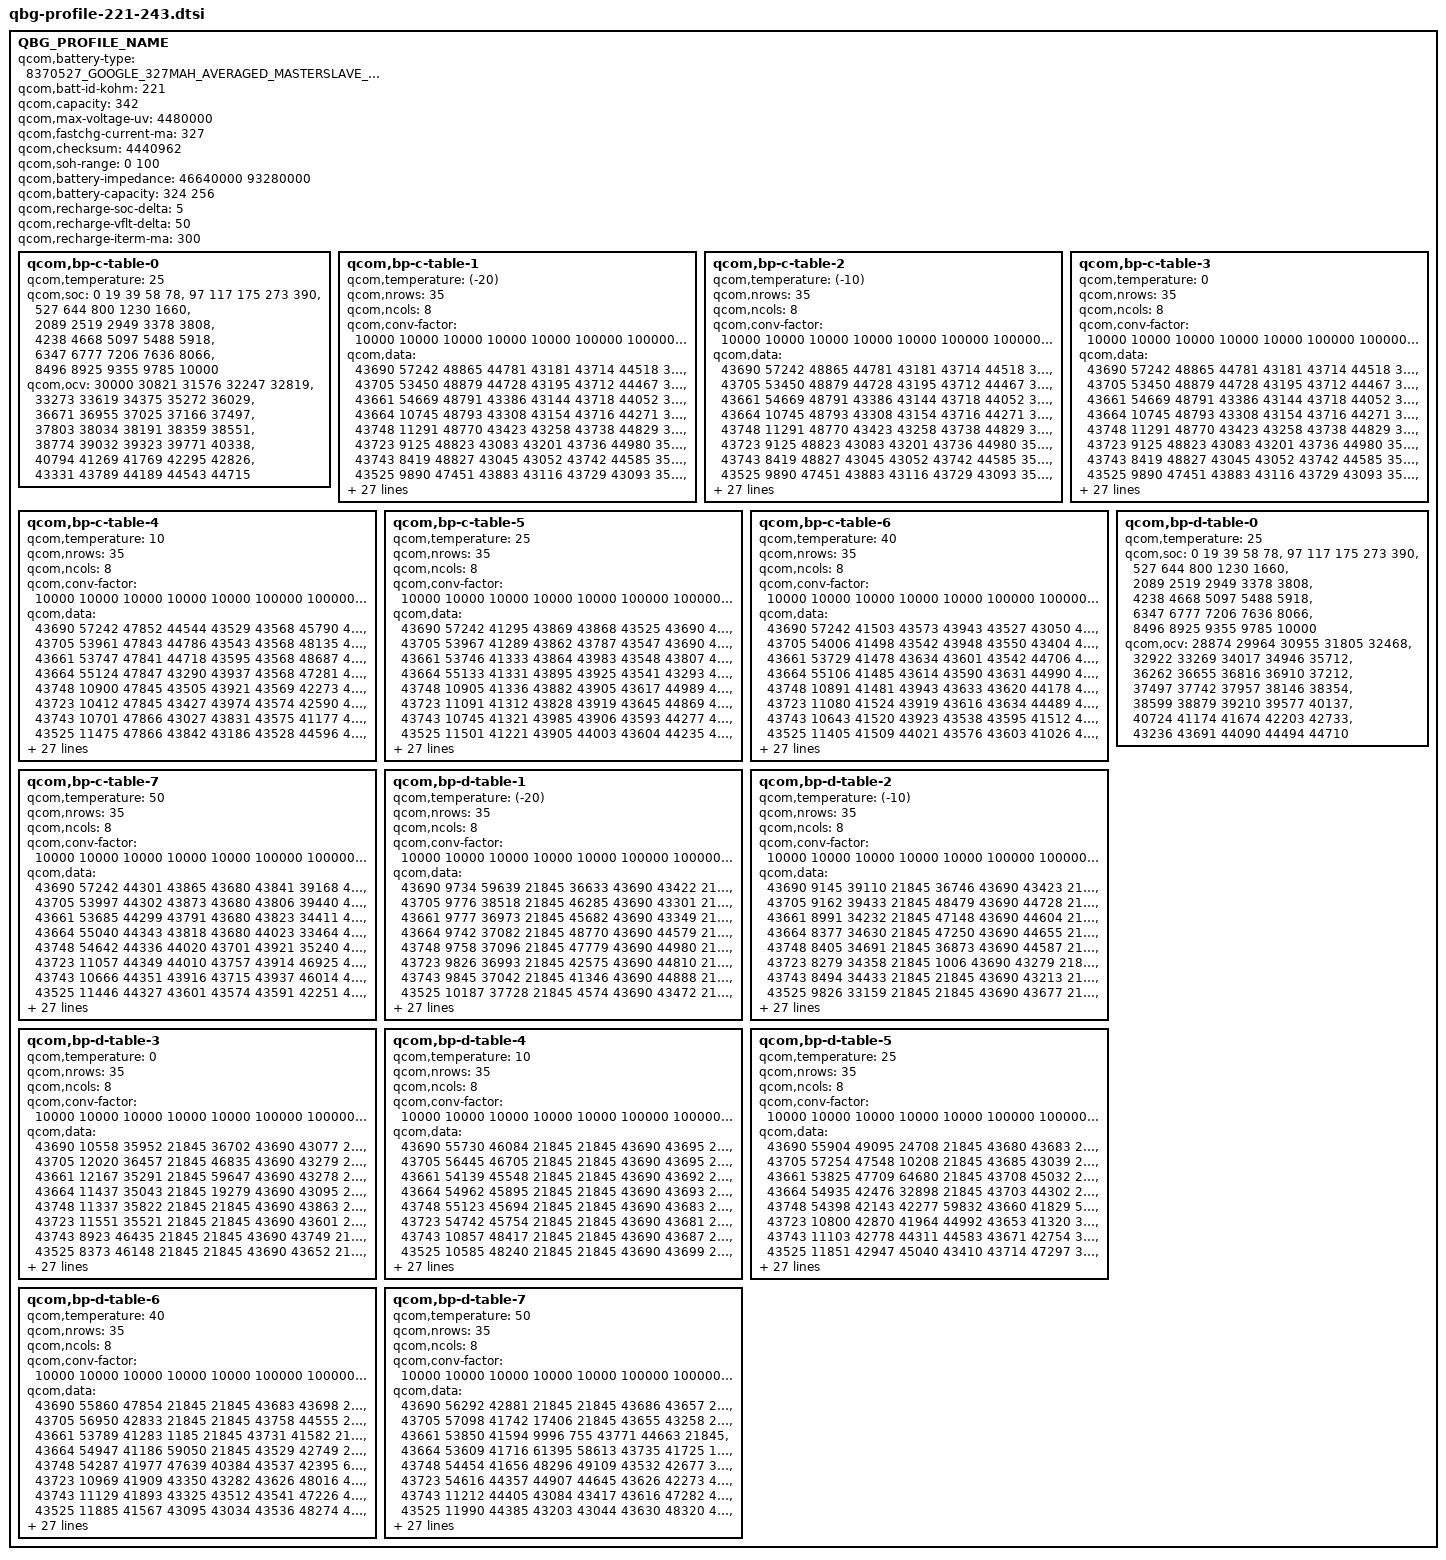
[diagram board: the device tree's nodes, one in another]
/*QBG Profiling Rev. 2.8*/

QBG_PROFILE_NAME {
	qcom,battery-type = "8370527_GOOGLE_327MAH_AVERAGED_MASTERSLAVE_MAR9TH2026";
	qcom,batt-id-kohm = <221>;
	qcom,capacity = <342>;
	qcom,max-voltage-uv = <4480000>;
	qcom,fastchg-current-ma = <327>;
	qcom,checksum = <4440962>; /*@5, 0.005V, 4% */
	qcom,soh-range = <0 100>;
	qcom,battery-impedance = <46640000 93280000>; /*Nominal_Impedance in 10nohm @ SOC 50% 25C* 0:fresh cell, 1: aged cell*/
	qcom,battery-capacity = <324 256>; /*Nominal_Capacity in mAh. 0: fresh cell, 1:aged cell*/ 
	qcom,recharge-soc-delta =<5>; /*SOC delta (in percent) dropped from EOC SOC to enable recharge*/ 
	qcom,recharge-vflt-delta =<50>; /*vfloat delta (in mV) dropped from regular vfloat in recharge*/ 
	qcom,recharge-iterm-ma = <300>; /*termination current (in mA) in recharge*/ 

	qcom,bp-c-table-0 {
		qcom,temperature = <25>;
		qcom,soc = <    0    19    39    58    78>,
			<   97   117   175   273   390>,
			<  527   644   800  1230  1660>,
			< 2089  2519  2949  3378  3808>,
			< 4238  4668  5097  5488  5918>,
			< 6347  6777  7206  7636  8066>,
			< 8496  8925  9355  9785 10000>;
		qcom,ocv = <30000 30821 31576 32247 32819>,
			<33273 33619 34375 35272 36029>,
			<36671 36955 37025 37166 37497>,
			<37803 38034 38191 38359 38551>,
			<38774 39032 39323 39771 40338>,
			<40794 41269 41769 42295 42826>,
			<43331 43789 44189 44543 44715>;
	};
	qcom,bp-c-table-1 {
		qcom,temperature = <(-20)>;
		qcom,nrows = <35>;
		qcom,ncols = <8>;
		qcom,conv-factor = <10000 10000 10000 10000 10000 100000 100000 10000>;
		qcom,data = <43690 57242 48865 44781 43181 43714 44518 34949>,
			<43705 53450 48879 44728 43195 43712 44467 35673>,
			<43661 54669 48791 43386 43144 43718 44052 35615>,
			<43664 10745 48793 43308 43154 43716 44271 35804>,
			<43748 11291 48770 43423 43258 43738 44829 35740>,
			<43723  9125 48823 43083 43201 43736 44980 35420>,
			<43743  8419 48827 43045 43052 43742 44585 35344>,
			<43525  9890 47451 43883 43116 43729 43093 35511>,
			<43963  9355 47456 44030 43131 43565 43225 46381>,
			<43820  9561 47435 43532 43474 43733 43834 46339>,
			<43173 14911 47432 43571 43473 43564 43809 46381>,
			<43054 14946 47475 43541 43506 43558 43807 46550>,
			<43402 15278 47474 43942 43437 43583 43189 46548>,
			<44644 14478 48650 43991 44551 43554 43804 35059>,
			<44246 14827 49111 41476 43820 43528 45996 36323>,
			<41603 16105 48957 41159 43843 43581 45625 33694>,
			<41853 15937 49052 41433 43200 43577 49052 33016>,
			<41263 16333 49107 41329 43104 43556 47500 33254>,
			<42904 16197 48934 42725 43451 43552 47156 34552>,
			<42058 15421 48914 42609 43501 43564 47219 34754>,
			<47652 15832 48984 42954 43511 43560 47503 33998>,
			<47254 12862 48306 42862 43466 43735 47241 34194>,
			<47427 12462 48165 42148 43476 43730 42561 39576>,
			<49114 12738 48216 42211 44713 43736 41580 39694>,
			<48564 14249 48533 42017 44610 43718 44201 39195>,
			<45665 13342 48402 42072 44865 43724 44544 40092>,
			<45267  2768 45809 42445 44454 43720 43342 37812>,
			<46732  2300 45668 42290 41510 43765 43409 38626>,
			<46974  3820 46029 42288 41018 43764 43012 38221>,
			<46376  3306 45914 47778 42526 43722 43221 61178>,
			<35738   670 45278 47705 42281 43723 43211 57531>,
			<34935   160 45123 48016 48769 43720 43161 64323>,
			<36385   274 45557 47628 46832 43722 43903 63135>,
			<35987  2018 45390 42845 34825 43760 43968 51678>,
			<36282  1198 45400 47649 48443 43715 43803 62626>;
	};
	qcom,bp-c-table-2 {
		qcom,temperature = <(-10)>;
		qcom,nrows = <35>;
		qcom,ncols = <8>;
		qcom,conv-factor = <10000 10000 10000 10000 10000 100000 100000 10000>;
		qcom,data = <43690 57242 48865 44781 43181 43714 44518 34949>,
			<43705 53450 48879 44728 43195 43712 44467 35673>,
			<43661 54669 48791 43386 43144 43718 44052 35615>,
			<43664 10745 48793 43308 43154 43716 44271 35804>,
			<43748 11291 48770 43423 43258 43738 44829 35740>,
			<43723  9125 48823 43083 43201 43736 44980 35420>,
			<43743  8419 48827 43045 43052 43742 44585 35344>,
			<43525  9890 47451 43883 43116 43729 43093 35511>,
			<43963  9355 47456 44030 43131 43565 43225 46381>,
			<43820  9561 47435 43532 43474 43733 43834 46339>,
			<43173 14911 47432 43571 43473 43564 43809 46381>,
			<43054 14946 47475 43541 43506 43558 43807 46550>,
			<43402 15278 47474 43942 43437 43583 43189 46548>,
			<44644 14478 48650 43991 44551 43554 43804 35059>,
			<44246 14827 49111 41476 43820 43528 45996 36323>,
			<41603 16105 48957 41159 43843 43581 45625 33694>,
			<41853 15937 49052 41433 43200 43577 49052 33016>,
			<41263 16333 49107 41329 43104 43556 47500 33254>,
			<42904 16197 48934 42725 43451 43552 47156 34552>,
			<42058 15421 48914 42609 43501 43564 47219 34754>,
			<47652 15832 48984 42954 43511 43560 47503 33998>,
			<47254 12862 48306 42862 43466 43735 47241 34194>,
			<47427 12462 48165 42148 43476 43730 42561 39576>,
			<49114 12738 48216 42211 44713 43736 41580 39694>,
			<48564 14249 48533 42017 44610 43718 44201 39195>,
			<45665 13342 48402 42072 44865 43724 44544 40092>,
			<45267  2768 45809 42445 44454 43720 43342 37812>,
			<46732  2300 45668 42290 41510 43765 43409 38626>,
			<46974  3820 46029 42288 41018 43764 43012 38221>,
			<46376  3306 45914 47778 42526 43722 43221 61178>,
			<35738   670 45278 47705 42281 43723 43211 57531>,
			<34935   160 45123 48016 48769 43720 43161 64323>,
			<36385   274 45557 47628 46832 43722 43903 63135>,
			<35987  2018 45390 42845 34825 43760 43968 51678>,
			<36282  1198 45400 47649 48443 43715 43803 62626>;
	};
	qcom,bp-c-table-3 {
		qcom,temperature = <0>;
		qcom,nrows = <35>;
		qcom,ncols = <8>;
		qcom,conv-factor = <10000 10000 10000 10000 10000 100000 100000 10000>;
		qcom,data = <43690 57242 48865 44781 43181 43714 44518 34949>,
			<43705 53450 48879 44728 43195 43712 44467 35673>,
			<43661 54669 48791 43386 43144 43718 44052 35615>,
			<43664 10745 48793 43308 43154 43716 44271 35804>,
			<43748 11291 48770 43423 43258 43738 44829 35740>,
			<43723  9125 48823 43083 43201 43736 44980 35420>,
			<43743  8419 48827 43045 43052 43742 44585 35344>,
			<43525  9890 47451 43883 43116 43729 43093 35511>,
			<43963  9355 47456 44030 43131 43565 43225 46381>,
			<43820  9561 47435 43532 43474 43733 43834 46339>,
			<43173 14911 47432 43571 43473 43564 43809 46381>,
			<43054 14946 47475 43541 43506 43558 43807 46550>,
			<43402 15278 47474 43942 43437 43583 43189 46548>,
			<44644 14478 48650 43991 44551 43554 43804 35059>,
			<44246 14827 49111 41476 43820 43528 45996 36323>,
			<41603 16105 48957 41159 43843 43581 45625 33694>,
			<41853 15937 49052 41433 43200 43577 49052 33016>,
			<41263 16333 49107 41329 43104 43556 47500 33254>,
			<42904 16197 48934 42725 43451 43552 47156 34552>,
			<42058 15421 48914 42609 43501 43564 47219 34754>,
			<47652 15832 48984 42954 43511 43560 47503 33998>,
			<47254 12862 48306 42862 43466 43735 47241 34194>,
			<47427 12462 48165 42148 43476 43730 42561 39576>,
			<49114 12738 48216 42211 44713 43736 41580 39694>,
			<48564 14249 48533 42017 44610 43718 44201 39195>,
			<45665 13342 48402 42072 44865 43724 44544 40092>,
			<45267  2768 45809 42445 44454 43720 43342 37812>,
			<46732  2300 45668 42290 41510 43765 43409 38626>,
			<46974  3820 46029 42288 41018 43764 43012 38221>,
			<46376  3306 45914 47778 42526 43722 43221 61178>,
			<35738   670 45278 47705 42281 43723 43211 57531>,
			<34935   160 45123 48016 48769 43720 43161 64323>,
			<36385   274 45557 47628 46832 43722 43903 63135>,
			<35987  2018 45390 42845 34825 43760 43968 51678>,
			<36282  1198 45400 47649 48443 43715 43803 62626>;
	};
	qcom,bp-c-table-4 {
		qcom,temperature = <10>;
		qcom,nrows = <35>;
		qcom,ncols = <8>;
		qcom,conv-factor = <10000 10000 10000 10000 10000 100000 100000 10000>;
		qcom,data = <43690 57242 47852 44544 43529 43568 45790 45257>,
			<43705 53961 47843 44786 43543 43568 48135 45186>,
			<43661 53747 47841 44718 43595 43568 48687 45893>,
			<43664 55124 47847 43290 43937 43568 47281 45853>,
			<43748 10900 47845 43505 43921 43569 42273 45867>,
			<43723 10412 47845 43427 43974 43574 42590 46049>,
			<43743 10701 47866 43027 43831 43575 41177 46002>,
			<43525 11475 47866 43842 43186 43528 44596 45614>,
			<43963  8359 47750 43585 43050 43527 43149 48394>,
			<43820 10157 47751 43628 43227 43630 43194 48514>,
			<43173  9685 47790 43563 43056 43643 43883 48254>,
			<43054 15070 47790 43725 43057 43596 43825 48168>,
			<43402 14864 42356 43576 43067 43638 43874 48175>,
			<44644 15312 42304 43022 43144 43547 44702 45753>,
			<44246 14336 42365 44806 43948 43536 46283 45843>,
			<41603 14715 42279 44279 43932 43524 46938 45212>,
			<41853 15878 42482 44158 44018 43520 45935 45266>,
			<41263 16285 42478 44469 43810 43532 48223 45182>,
			<42904 16236 42378 44536 43805 43529 48676 45494>,
			<42058 15582 42382 44348 43895 43530 48764 45370>,
			<47652 15847 42386 44353 43863 43574 48378 46776>,
			<47254 13030 42472 41671 43175 43570 47047 46613>,
			<47427 13162 42495 41477 43178 43577 46766 47012>,
			<49114 12764 42452 41577 43859 43558 47616 47086>,
			<48564 14310 42260 41544 43207 43566 41896 46213>,
			<45665 13732 47776 41983 43092 43734 44049 46386>,
			<45267  2638 47867 41853 43324 43742 45009 35714>,
			<46732  2168 47668 41166 44696 43717 44647 34934>,
			<46974  3709 47706 41062 44624 43718 44695 36352>,
			<46376  3138 48114 41403 44221 43713 43285 35941>,
			<35738   591 47968 41469 44307 43713 43460 33586>,
			<34935    29 47294 41418 41001 43717 43440 34593>,
			<36385  1736 47250 41098 42264 43732 43245 39124>,
			<35987  1866 47321 44180 48887 43640 44022 40929>,
			<36282  1244 47324 44583 47925 43712 43605 39795>;
	};
	qcom,bp-c-table-5 {
		qcom,temperature = <25>;
		qcom,nrows = <35>;
		qcom,ncols = <8>;
		qcom,conv-factor = <10000 10000 10000 10000 10000 100000 100000 10000>;
		qcom,data = <43690 57242 41295 43869 43868 43525 43690 47732>,
			<43705 53967 41289 43862 43787 43547 43690 47636>,
			<43661 53746 41333 43864 43983 43548 43807 47670>,
			<43664 55133 41331 43895 43925 43541 43293 47827>,
			<43748 10905 41336 43882 43905 43617 44989 47868>,
			<43723 11091 41312 43828 43919 43645 44869 47769>,
			<43743 10745 41321 43985 43906 43593 44277 47800>,
			<43525 11501 41221 43905 44003 43604 44235 42346>,
			<43963  9058 41271 43570 43902 43604 43165 42460>,
			<43820  9751 41256 43552 43902 43943 43198 42384>,
			<43173  9621 41413 43621 43982 43909 43503 42049>,
			<43054 15089 41470 43631 43986 43923 43033 42101>,
			<43402 14859 41466 43592 44002 43961 44874 42003>,
			<44644 15236 41449 43109 43595 43631 47856 47864>,
			<44246 14547 41355 43292 43949 43548 47577 48104>,
			<41603 14593 41048 44686 43957 43527 47398 47923>,
			<41853 15928 41059 44788 43957 43520 48883 47879>,
			<41263 16261 40965 44744 43934 43520 47113 47885>,
			<42904 16253 41017 44780 43971 43521 42956 47880>,
			<42058 15421 41169 44691 43791 43521 41461 47888>,
			<47652 15836 41154 44775 43874 43523 42529 47945>,
			<47254 13010 41201 44585 43887 43522 47732 47288>,
			<47427 13105 41208 44618 43788 43526 35655 47336>,
			<49114 12785 41210 44547 43998 43526 45981 47945>,
			<48564 14136 41210 44765 43998 43534 41537 47874>,
			<45665 13808 41212 44667 43897 43580 44032 47315>,
			<45267  2975 41154 44934 43165 43558 45046 47602>,
			<46732  2435 41007 44827 43049 43566 44981 48871>,
			<46974  3997 40963 44204 43103 43733 44596 49045>,
			<46376  3552 41085 44226 43480 43733 44600 48381>,
			<35738  1001 41377 44241 44789 43560 44680 48392>,
			<34935   423 41369 44226 44913 43555 43267 46048>,
			<36385  1591 41416 44164 41956 43577 43395 46696>,
			<35987  1877 41267 44643 41561 43579 43445 45346>,
			<36282  1025 41429 43409 41330 43555 43810 46990>;
	};
	qcom,bp-c-table-6 {
		qcom,temperature = <40>;
		qcom,nrows = <35>;
		qcom,ncols = <8>;
		qcom,conv-factor = <10000 10000 10000 10000 10000 100000 100000 10000>;
		qcom,data = <43690 57242 41503 43573 43943 43527 43050 40961>,
			<43705 54006 41498 43542 43948 43550 43404 41060>,
			<43661 53729 41478 43634 43601 43542 44706 41024>,
			<43664 55106 41485 43614 43590 43631 44990 41386>,
			<43748 10891 41481 43943 43633 43620 44178 41403>,
			<43723 11080 41524 43919 43616 43634 44489 41398>,
			<43743 10643 41520 43923 43538 43595 41512 41358>,
			<43525 11405 41509 44021 43576 43603 41026 41346>,
			<43963  9013 41514 44011 43552 43966 41039 41048>,
			<43820  9764 41693 43966 43535 43906 41634 41081>,
			<43173  9638 41671 43624 43608 43954 44985 41066>,
			<43054 15086 41677 43939 43730 43930 41994 41004>,
			<43402 14884 41675 43595 43543 43604 41300 40971>,
			<44644 15279 41719 43804 43610 43597 41174 41314>,
			<44246 14564 41696 43197 43957 43622 40997 42737>,
			<41603 14805 41630 43249 43959 43625 42755 42528>,
			<41853 16071 41655 43216 43948 43540 47726 42531>,
			<41263 16268 41632 43215 43967 43540 41309 42718>,
			<42904 16207 44369 43260 44007 43627 41535 42532>,
			<42058 15387 44358 43859 43852 43631 44940 42602>,
			<47652 15674 44361 43137 43179 43539 44036 42912>,
			<47254 12851 44406 43208 43865 43551 41881 42907>,
			<47427 13154 44400 43110 43801 43550 47174 43006>,
			<49114 12594 44403 43044 43994 43548 42711 42609>,
			<48564 14107 44401 43159 43973 43549 44992 42559>,
			<45665 13781 44407 43164 43789 43550 44679 42517>,
			<45267  3062 44406 43254 43843 43533 43321 42988>,
			<46732  2545 44362 43128 43153 43571 43490 42121>,
			<46974  4038 44353 43420 43047 43577 43417 42054>,
			<46376  3536 44374 43378 43008 43579 44720 42260>,
			<35738   966 41656 44678 43445 43569 44796 47676>,
			<34935   388 41601 44687 44728 43532 44734 47926>,
			<36385  1552 41621 43354 44198 43550 43318 47608>,
			<35987  1208 41678 43111 45000 43521 43473 47876>,
			<36282  1133 41704 43152 44319 43543 43895 47588>;
	};
	qcom,bp-c-table-7 {
		qcom,temperature = <50>;
		qcom,nrows = <35>;
		qcom,ncols = <8>;
		qcom,conv-factor = <10000 10000 10000 10000 10000 100000 100000 10000>;
		qcom,data = <43690 57242 44301 43865 43680 43841 39168 41559>,
			<43705 53997 44302 43873 43680 43806 39440 41859>,
			<43661 53685 44299 43791 43680 43823 34411 41956>,
			<43664 55040 44343 43818 43680 44023 33464 41924>,
			<43748 54642 44336 44020 43701 43921 35240 41773>,
			<43723 11057 44349 44010 43757 43914 46925 41782>,
			<43743 10666 44351 43916 43715 43937 46014 41734>,
			<43525 11446 44327 43601 43574 43591 42251 41833>,
			<43963  8978 44334 43939 43739 43914 42750 41778>,
			<43820  9757 44496 43937 43740 43908 48642 41790>,
			<43173  9601 44510 43547 43551 43969 44855 41922>,
			<43054 14979 44506 43625 43741 44007 41397 41874>,
			<43402 15051 44484 43594 43712 44014 48032 41954>,
			<44644 14919 44480 44027 43604 43947 41709 41152>,
			<44246 14487 44533 43811 43952 43589 41516 41071>,
			<41603 14793 44537 43795 43963 43598 42906 41032>,
			<41853 16126 44514 43805 43951 43637 42812 41081>,
			<41263 16268 44433 43806 43604 43636 40964 40980>,
			<42904 16196 44421 43805 43956 43592 41599 41077>,
			<42058 15466 44430 44010 43851 43610 44684 41398>,
			<47652 15618 44468 43977 43859 43632 45020 41468>,
			<47254 12819 44464 43779 43890 43642 41665 41424>,
			<47427 13146 44476 43169 43833 43642 47991 41274>,
			<49114 12665 44479 43899 43923 43641 41186 41045>,
			<48564 14206 44478 43988 44015 43634 44557 41061>,
			<45665 13579 44478 43999 43819 43647 43310 41048>,
			<45267  2858 44477 43778 43838 43630 43298 41462>,
			<46732  2518 44465 43191 43786 43546 43380 41304>,
			<46974  3873 44469 43058 43868 43530 43366 42623>,
			<46376  3391 44429 43079 43234 43572 43346 42793>,
			<35738   983 44441 43513 43068 43531 44653 42218>,
			<34935   402 44522 43463 43499 43551 44564 42400>,
			<36385  1552 44538 43496 44562 43623 44774 47852>,
			<35987  1211 44488 43147 44726 43628 43365 42046>,
			<36282  1127 44475 43839 44196 43593 43840 42343>;
	};
	qcom,bp-d-table-0 {
		qcom,temperature = <25>;
		qcom,soc = <    0    19    39    58    78>,
			<   97   117   175   273   390>,
			<  527   644   800  1230  1660>,
			< 2089  2519  2949  3378  3808>,
			< 4238  4668  5097  5488  5918>,
			< 6347  6777  7206  7636  8066>,
			< 8496  8925  9355  9785 10000>;
		qcom,ocv = <28874 29964 30955 31805 32468>,
			<32922 33269 34017 34946 35712>,
			<36262 36655 36816 36910 37212>,
			<37497 37742 37957 38146 38354>,
			<38599 38879 39210 39577 40137>,
			<40724 41174 41674 42203 42733>,
			<43236 43691 44090 44494 44710>;
	};
	qcom,bp-d-table-1 {
		qcom,temperature = <(-20)>;
		qcom,nrows = <35>;
		qcom,ncols = <8>;
		qcom,conv-factor = <10000 10000 10000 10000 10000 100000 100000 10000>;
		qcom,data = <43690  9734 59639 21845 36633 43690 43422 21845>,
			<43705  9776 38518 21845 46285 43690 43301 21845>,
			<43661  9777 36973 21845 45682 43690 43349 21845>,
			<43664  9742 37082 21845 48770 43690 44579 21845>,
			<43748  9758 37096 21845 47779 43690 44980 21845>,
			<43723  9826 36993 21845 42575 43690 44810 21845>,
			<43743  9845 37042 21845 41346 43690 44888 21845>,
			<43525 10187 37728 21845  4574 43690 43472 21845>,
			<43963  9362 37876 21845 21845 43690 43771 21845>,
			<43820  9227 37409 21845 13610 43690 43728 21845>,
			<43173  9646 40424 21845 63073 43690 43583 21845>,
			<43054  9673 39976 21845 60385 43690 43631 21845>,
			<43402  9594 40587 21845 33228 43690 43957 21845>,
			<44644 14873 39813 19482 36073 43691 43878 21845>,
			<44246 15315 39593  8582 46933 43691 43208 21845>,
			<41603 14517 33949 51926 48418 43688 43106 21845>,
			<41853 14442 32882 60872 47253 43688 43411 17637>,
			<41263 14792 33754 40194 42004 43689 43275 24682>,
			<42904 16038 33341 34573 42497 43694 43362  6184>,
			<42058 15983 36136 35896 41374 43694 44713  2767>,
			<47652 16187 35842 35805 41133 43695 44769 14544>,
			<47254 15569 36083 46209 41488 43692 44638 11624>,
			<47427 15627 35982 46842 44335 43693 44152 54558>,
			<49114 12887 36652 45560 44479 43682 41921 53397>,
			<48564 12316 36377 45220 44510 43683 41398 57292>,
			<45665 13851 36387 45852 41700 43683 42550 56877>,
			<45267 13412 36399 45930 41969 43680 42601 57254>,
			<46732  2655 36374 45229 41189 43681 42540 56502>,
			<46974  2442 36477 45254 41389 43686 42640 56406>,
			<46376  4077 36548 45106 41279 43687 41280 56599>,
			<35738  3582 36407 45272 42685 43685 40986 54003>,
			<34935  1019 36509 45102 41311 43704 41921 53953>,
			<36385   405 36482 45461 41121 43685 44370 56388>,
			<35987  2015 36569 46641 44224 43683 44285 55642>,
			<36282  1055 36472 47010 45019 43695 45014 55711>;
	};
	qcom,bp-d-table-2 {
		qcom,temperature = <(-10)>;
		qcom,nrows = <35>;
		qcom,ncols = <8>;
		qcom,conv-factor = <10000 10000 10000 10000 10000 100000 100000 10000>;
		qcom,data = <43690  9145 39110 21845 36746 43690 43423 21845>,
			<43705  9162 39433 21845 48479 43690 44728 21845>,
			<43661  8991 34232 21845 47148 43690 44604 21845>,
			<43664  8377 34630 21845 47250 43690 44655 21845>,
			<43748  8405 34691 21845 36873 43690 44587 21845>,
			<43723  8279 34358 21845  1006 43690 43279 21845>,
			<43743  8494 34433 21845 21845 43690 43213 21845>,
			<43525  9826 33159 21845 21845 43690 43677 21845>,
			<43963 10060 33606 21845 30777 43690 43713 21845>,
			<43820  9239 33352 21845 63943 43690 43645 21845>,
			<43173  9702 36120 21845 35923 43690 44011 21845>,
			<43054  9479 36025 21845 48471 43690 43795 21845>,
			<43402 14984 36552 11786 42064 43690 43067 21845>,
			<44644 15268 35425 40554 41323 43688 43388 25476>,
			<44246 15120 46110 35597 41957 43689 44562 14988>,
			<41603 14591 47061 45958 44346 43692 44614 56950>,
			<41853 14427 46623 47434 44286 43682 44974 52782>,
			<41263 14655 46628 47729 44918 43680 44632 61720>,
			<42904 16098 46635 42284 44630 43684 44889 64558>,
			<42058 16270 46647 41998 44744 43705 41634 63776>,
			<47652 15588 46603 42769 44723 43666 42768 63643>,
			<47254 15646 46632 42908 44722 43719 47206 64278>,
			<47427 13232 46648 42911 44668 43738 42352 64266>,
			<49114 12320 46653 42969 45052 43743 42111 64379>,
			<48564 14074 46696 42155 44892 43743 42829 63695>,
			<45665 13469 46609 41999 44070 43737 42689 63562>,
			<45267  2786 46695 42297 44124 43738 42725 63788>,
			<46732  2245 46690 47669 44541 43713 42700 65233>,
			<46974  3640 46800 48081 44384 43727 41334 65343>,
			<46376  3075 46795 47248 41607 43722 41457 64528>,
			<35738   574 46847 47182 41676 43761 41165 64881>,
			<34935   232 46842 47499 41625 43774 41473 64834>,
			<36385   370 46764 47527 44138 43750 41720 64925>,
			<35987  1797 45528 47123 43350 43755 41566 65300>,
			<36282  1044 45471 47325 43429 43670 41822 65517>;
	};
	qcom,bp-d-table-3 {
		qcom,temperature = <0>;
		qcom,nrows = <35>;
		qcom,ncols = <8>;
		qcom,conv-factor = <10000 10000 10000 10000 10000 100000 100000 10000>;
		qcom,data = <43690 10558 35952 21845 36702 43690 43077 21845>,
			<43705 12020 36457 21845 46835 43690 43279 21845>,
			<43661 12167 35291 21845 59647 43690 43278 21845>,
			<43664 11437 35043 21845 19279 43690 43095 21845>,
			<43748 11337 35822 21845 21845 43690 43863 21845>,
			<43723 11551 35521 21845 21845 43690 43601 21845>,
			<43743  8923 46435 21845 21845 43690 43749 21845>,
			<43525  8373 46148 21845 21845 43690 43652 21845>,
			<43963  9881 46937 21845  5808 43690 43768 21845>,
			<43820  9389 46627 21845 40155 43690 43588 21845>,
			<43173  9662 45326 21845 48712 43690 43894 21845>,
			<43054  9686 45492 56252 41036 43690 43086 21845>,
			<43402  9589 45246 36075 44132 43691 43287  7108>,
			<44644 14948 48436 41077 43374 43692 44210 65288>,
			<44246 15150 48175 42711 43308 43684 44470 59064>,
			<41603 14483 48281 41927 43026 43762 40973 60249>,
			<41853 14770 48365 41964 43060 43743 49099 38821>,
			<41263 14708 48175 41871 43014 43729 48174 37050>,
			<42904 15877 48172 41897 43087 43733 48767 37589>,
			<42058 16139 48348 41543 43412 43560 47248 40227>,
			<47652 15375 48160 41598 43323 43561 42865 39966>,
			<47254 15736 48344 41563 43386 43567 41335 40087>,
			<47427 13191 48184 41954 44731 43561 40966 40097>,
			<49114 12339 48131 41834 44774 43560 41168 40162>,
			<48564 14065 48187 41186 44568 43732 41731 39955>,
			<45665 13560 48172 41382 44968 43731 41791 40392>,
			<45267  2759 48171 41332 45025 43737 41780 37602>,
			<46732  2098 48323 42530 44854 43718 41961 37778>,
			<46974  3692 48279 42931 44914 43725 41543 37727>,
			<46376  3147 48279 42968 44881 43720 41675 36898>,
			<35738   633 48376 42773 44882 43765 44365 37261>,
			<34935    56 48259 42822 44849 43767 41711 37270>,
			<36385  1724 48264 42962 44568 43761 41517 36919>,
			<35987  1902 48354 42735 43408 43762 41520 37760>,
			<36282  1040 48335 41343 43221 43772 41711 37480>;
	};
	qcom,bp-d-table-4 {
		qcom,temperature = <10>;
		qcom,nrows = <35>;
		qcom,ncols = <8>;
		qcom,conv-factor = <10000 10000 10000 10000 10000 100000 100000 10000>;
		qcom,data = <43690 55730 46084 21845 21845 43690 43695 21845>,
			<43705 56445 46705 21845 21845 43690 43695 21845>,
			<43661 54139 45548 21845 21845 43690 43692 21845>,
			<43664 54962 45895 21845 21845 43690 43693 21845>,
			<43748 55123 45694 21845 21845 43690 43683 21845>,
			<43723 54742 45754 21845 21845 43690 43681 21845>,
			<43743 10857 48417 21845 21845 43690 43687 21845>,
			<43525 10585 48240 21845 21845 43690 43699 21845>,
			<43963 11613 48911 21845  4029 43690 43724 21845>,
			<43820  8600 48869 21845 46725 43690 43970 21845>,
			<43173 10096 47602 61539 41661 43691 43464 20878>,
			<43054  9613 47541 45501 44838 43688 44573 16005>,
			<43402  9476 47258 44176 43490 43681 44060 57745>,
			<44644 15007 47263 44611 43989 43720 41019 33703>,
			<44246 15297 47911 44279 43868 43734 47727 36108>,
			<41603 14551 48115 44284 43011 43552 47662 36432>,
			<41853 14827 48023 44260 43119 43579 47773 35307>,
			<41263 14685 48017 44281 43025 43583 47641 34968>,
			<42904 15894 48017 44258 43130 43570 42448 35627>,
			<42058 16186 48024 44172 43083 43570 41318 35454>,
			<47652 15394 48000 44186 43125 43570 41104 35528>,
			<47254 15617 48013 44276 43128 43581 41125 35483>,
			<47427 12887 48056 44094 43127 43583 41844 35457>,
			<49114 12494 48058 44140 43428 43557 41770 35583>,
			<48564 13979 48056 44431 43503 43556 41793 35449>,
			<45665 13541 48034 44378 43474 43557 42923 35693>,
			<45267  2598 47681 41518 43371 43556 42471 34844>,
			<46732  2100 47683 41516 44707 43561 41081 35242>,
			<46974  3614 47698 41669 44691 43729 41602 35302>,
			<46376  3173 47713 41475 43357 43732 44382 35109>,
			<35738   609 47683 41541 43266 43735 41483 36524>,
			<34935    39 48040 41497 43327 43729 41658 36488>,
			<36385  1712 47699 41719 43413 43729 41688 36523>,
			<35987  1813 47726 41641 43043 43733 41194 35126>,
			<36282  1036 47665 44415 43233 43560 41434 35268>;
	};
	qcom,bp-d-table-5 {
		qcom,temperature = <25>;
		qcom,nrows = <35>;
		qcom,ncols = <8>;
		qcom,conv-factor = <10000 10000 10000 10000 10000 100000 100000 10000>;
		qcom,data = <43690 55904 49095 24708 21845 43680 43683 21845>,
			<43705 57254 47548 10208 21845 43685 43039 21845>,
			<43661 53825 47709 64680 21845 43708 45032 21845>,
			<43664 54935 42476 32898 21845 43703 44302 21845>,
			<43748 54398 42143 42277 59832 43660 41829 54050>,
			<43723 10800 42870 41964 44992 43653 41320 39648>,
			<43743 11103 42778 44311 44583 43671 42754 32943>,
			<43525 11851 42947 45040 43410 43714 47297 35473>,
			<43963  8744 42934 44737 43069 43566 48607 45246>,
			<43820  8490 42519 44687 43132 43530 47043 45822>,
			<43173  9996 42510 43293 43834 43574 48599 49100>,
			<43054  9605 42739 43375 43809 43520 42503 48737>,
			<43402  9594 42653 43322 43979 43520 42735 47425>,
			<44644 14980 42664 43083 43627 43523 47718 47902>,
			<44246 15350 41244 43459 43812 43535 41327 47118>,
			<41603 14547 41436 43315 43173 43546 42744 47219>,
			<41853 14788 41471 43284 43045 43538 42578 47506>,
			<41263 16111 41453 43382 43025 43543 42768 47562>,
			<42904 16296 41366 43366 43039 43537 41388 47497>,
			<42058 16248 41354 43368 43225 43536 41781 47131>,
			<47652 15469 41389 43333 43194 43536 41059 47304>,
			<47254 15733 41385 43337 43842 43548 41147 47287>,
			<47427 13184 41049 43331 43894 43544 41143 47271>,
			<49114 12339 41039 44711 43867 43546 41448 47251>,
			<48564 13923 41085 44593 43104 43546 47148 47410>,
			<45665 13758 41060 44634 43323 43524 48975 48669>,
			<45267  2684 41063 44548 43486 43531 41263 48842>,
			<46732  2144 41082 44603 43500 43572 41703 48779>,
			<46974  3697 41079 44554 43103 43530 44483 48810>,
			<46376  3143 41049 44648 43045 43531 44511 47477>,
			<35738   590 41387 44636 43169 43529 41876 47378>,
			<34935     1 41355 44662 43850 43528 41139 47375>,
			<36385  1680 41446 44553 43891 43529 41110 47370>,
			<35987  1892 41430 44793 43888 43529 41117 47374>,
			<36282  1036 41279 44685 43892 43534 41102 47366>;
	};
	qcom,bp-d-table-6 {
		qcom,temperature = <40>;
		qcom,nrows = <35>;
		qcom,ncols = <8>;
		qcom,conv-factor = <10000 10000 10000 10000 10000 100000 100000 10000>;
		qcom,data = <43690 55860 47854 21845 21845 43683 43698 21845>,
			<43705 56950 42833 21845 21845 43758 44555 21845>,
			<43661 53789 41283  1185 21845 43731 41582 21845>,
			<43664 54947 41186 59050 21845 43529 42749 21845>,
			<43748 54287 41977 47639 40384 43537 42395 63864>,
			<43723 10969 41909 43350 43282 43626 48016 47334>,
			<43743 11129 41893 43325 43512 43541 47226 48112>,
			<43525 11885 41567 43095 43034 43536 48274 42314>,
			<43963  8955 41590 43014 43859 43545 45896 42040>,
			<43820  8693 41491 43041 43167 43536 46954 42194>,
			<43173 10041 41525 43216 43800 43625 35771 42777>,
			<43054  9301 41529 43048 43602 43543 41994 42579>,
			<43402  9590 41507 43056 43962 43626 41286 42891>,
			<44644 14989 41689 43776 43572 43635 42272 41250>,
			<44246 15343 41726 43152 43909 43633 42930 42529>,
			<41603 14536 41620 43144 43796 43635 41787 42585>,
			<41853 14798 41626 43246 43189 43599 41823 42957>,
			<41263 16066 41602 43206 43017 43605 41949 42158>,
			<42904 16258 41652 43021 43232 43954 41768 42816>,
			<42058 16209 41662 43118 43847 43951 40972 42804>,
			<47652 15448 41633 43032 43803 43589 41444 42977>,
			<47254 12974 41640 43070 43973 43634 41468 42568>,
			<47427 13289 44374 43051 44000 43641 41281 42508>,
			<49114 12415 44381 43031 43814 43633 47875 42891>,
			<48564 13913 44379 43121 43027 43621 47877 42204>,
			<45665 13395 44357 43060 43460 43548 41494 42078>,
			<45267  2656 44378 43066 43500 43537 44081 42000>,
			<46732  2158 44377 43439 43041 43647 44437 42019>,
			<46974  3683 44368 43475 43801 43633 41966 42130>,
			<46376  3197 41647 43267 43919 43631 42853 42821>,
			<35738   614 41657 43411 44011 43525 41186 42807>,
			<34935    63 41615 43126 43924 43521 41115 43002>,
			<36385  1665 41628 43032 43905 43546 42735 42930>,
			<35987  1811 41711 43025 43938 43627 48037 42578>,
			<36282  1065 41702 43086 43603 43618 47311 42591>;
	};
	qcom,bp-d-table-7 {
		qcom,temperature = <50>;
		qcom,nrows = <35>;
		qcom,ncols = <8>;
		qcom,conv-factor = <10000 10000 10000 10000 10000 100000 100000 10000>;
		qcom,data = <43690 56292 42881 21845 21845 43686 43657 21845>,
			<43705 57098 41742 17406 21845 43655 43258 21845>,
			<43661 53850 41594  9996   755 43771 44663 21845>,
			<43664 53609 41716 61395 58613 43735 41725 13610>,
			<43748 54454 41656 48296 49109 43532 42677 39282>,
			<43723 54616 44357 44907 44645 43626 42273 47170>,
			<43743 11212 44405 43084 43417 43616 47282 42402>,
			<43525 11990 44385 43203 43044 43630 48320 42772>,
			<43963  8873 44316 43188 43849 43628 45234 42506>,
			<43820  8633 44296 43861 43858 43619 46677 42692>,
			<43173 10186 44327 43859 43890 43640 35586 42626>,
			<43054  9326 44328 43170 43642 43622 48376 41374>,
			<43402  9490 44500 43250 43641 43619 42442 41259>,
			<44644 15020 44485 43922 43579 43607 47722 41804>,
			<44246 15242 44534 43781 43960 43601 41277 41087>,
			<41603 14572 44513 43896 43994 43944 41370 41448>,
			<41853 14827 44520 43874 43807 43956 41834 41412>,
			<41263 16119 44437 43149 43172 44017 41729 42647>,
			<42904 16379 44434 43058 43170 44013 42773 42504>,
			<42058 15498 44440 43243 43168 43958 41952 42732>,
			<47652 15780 44421 43233 43814 43963 41168 41338>,
			<47254 12982 44423 43146 43935 43591 41071 41441>,
			<47427 13298 44419 43847 43955 43592 41455 41042>,
			<49114 12372 44431 43137 43985 43611 47984 41227>,
			<48564 14258 44427 43158 43011 43591 48060 42615>,
			<45665 13736 44426 43182 43407 43647 44527 42894>,
			<45267  2673 44426 43208 43068 43610 44427 42923>,
			<46732  2147 44426 43430 43989 43942 41114 42503>,
			<46974  3706 44428 43455 43918 43634 41401 42743>,
			<46376  3188 44422 43079 43589 43548 42813 42656>,
			<35738   633 44446 43063 43595 43547 42180 41243>,
			<34935    48 44439 43232 43594 43537 42201 41463>,
			<36385  1664 44515 43183 43584 43617 42865 41355>,
			<35987  1822 44530 43877 43944 43639 42689 41047>,
			<36282  1236 44491 43792 43939 43597 42659 41043>;
	};
};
